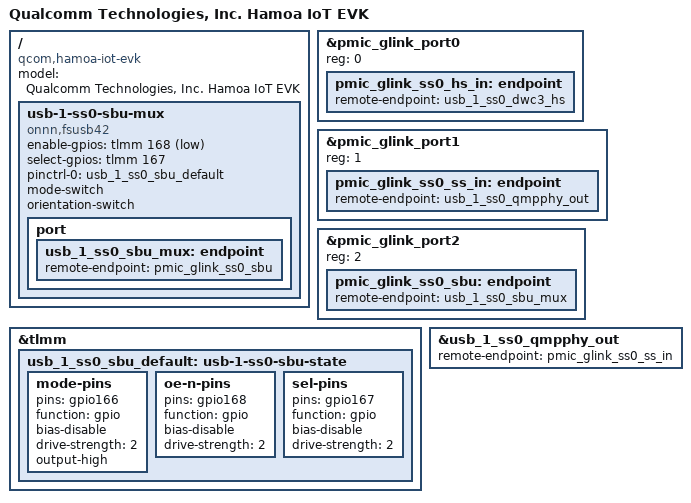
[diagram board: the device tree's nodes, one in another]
// SPDX-License-Identifier: BSD-3-Clause
/*
 * Copyright (c) Qualcomm Technologies, Inc. and/or its subsidiaries.
 */

/dts-v1/;

#include "hamoa-iot-som.dtsi"
#include "iq-x-iot-evk.dtsi"

/ {
	model = "Qualcomm Technologies, Inc. Hamoa IoT EVK";
	compatible = "qcom,hamoa-iot-evk",
		     "qcom,hamoa-iot-som",
		     "qcom,x1e80100";

	usb-1-ss0-sbu-mux {
		compatible = "onnn,fsusb42", "gpio-sbu-mux";

		enable-gpios = <&tlmm 168 GPIO_ACTIVE_LOW>;
		select-gpios = <&tlmm 167 GPIO_ACTIVE_HIGH>;

		pinctrl-0 = <&usb_1_ss0_sbu_default>;
		pinctrl-names = "default";

		mode-switch;
		orientation-switch;

		port {
			usb_1_ss0_sbu_mux: endpoint {
				remote-endpoint = <&pmic_glink_ss0_sbu>;
			};
		};
	};
};


&pmic_glink_port0 {
	reg = <0>;
	pmic_glink_ss0_hs_in: endpoint {
		remote-endpoint = <&usb_1_ss0_dwc3_hs>;
	};
};
&pmic_glink_port1 {
	reg = <1>;
	pmic_glink_ss0_ss_in: endpoint {
		remote-endpoint = <&usb_1_ss0_qmpphy_out>;
	};
};
&pmic_glink_port2 {
	reg = <2>;
	pmic_glink_ss0_sbu: endpoint {
		remote-endpoint = <&usb_1_ss0_sbu_mux>;
	};
};

&tlmm {
	usb_1_ss0_sbu_default: usb-1-ss0-sbu-state {
		mode-pins {
			pins = "gpio166";
			function = "gpio";
			bias-disable;
			drive-strength = <2>;
			output-high;
		};

		oe-n-pins {
			pins = "gpio168";
			function = "gpio";
			bias-disable;
			drive-strength = <2>;
		};

		sel-pins {
			pins = "gpio167";
			function = "gpio";
			bias-disable;
			drive-strength = <2>;
		};
	};
};


&usb_1_ss0_qmpphy_out {
	remote-endpoint = <&pmic_glink_ss0_ss_in>;
};
